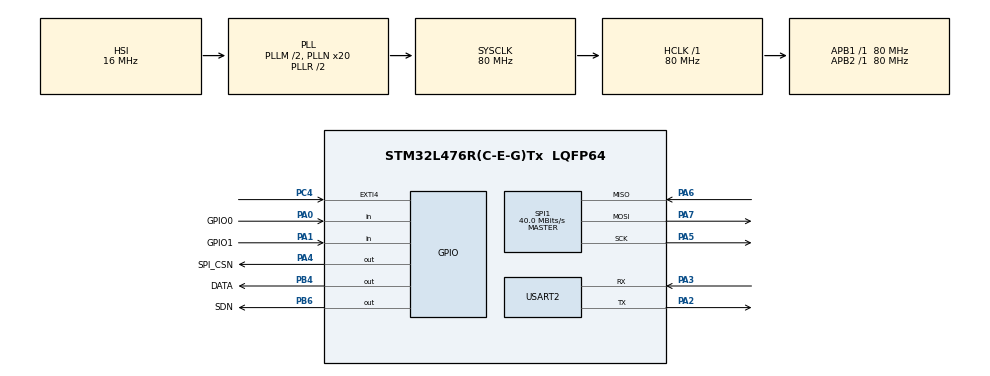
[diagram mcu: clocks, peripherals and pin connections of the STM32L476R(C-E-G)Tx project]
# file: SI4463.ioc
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Mcu.Family=STM32L4
Mcu.Name=STM32L476R(C-E-G)Tx
Mcu.Package=LQFP64
NVIC.EXTI4_IRQn=true\:1\:1\:true\:false\:true\:true\:true
NVIC.PriorityGroup=NVIC_PRIORITYGROUP_2
PA0.GPIO_Label=GPIO0
PA0.GPIO_PuPd=GPIO_PULLUP
PA0.Signal=GPIO_Input
PA1.GPIO_Label=GPIO1
PA1.GPIO_PuPd=GPIO_PULLUP
PA1.Signal=GPIO_Input
PA13.Mode=Serial-Wire
PA13.Signal=SYS_JTMS-SWDIO
PA14.Mode=Serial-Wire
PA14.Signal=SYS_JTCK-SWCLK
PA2.Mode=Asynchronous
PA2.Signal=USART2_TX
PA3.Mode=Asynchronous
PA3.Signal=USART2_RX
PA4.GPIO_Label=SPI_CSN
PA4.GPIO_PuPd=GPIO_PULLUP
PA4.GPIO_Speed=GPIO_SPEED_HIGH
PA4.Signal=GPIO_Output
PA5.GPIO_PuPd=GPIO_PULLUP
PA5.Mode=Full_Duplex_Master
PA5.Signal=SPI1_SCK
PA6.GPIO_PuPd=GPIO_PULLUP
PA6.Mode=Full_Duplex_Master
PA6.Signal=SPI1_MISO
PA7.GPIO_PuPd=GPIO_PULLUP
PA7.Mode=Full_Duplex_Master
PA7.Signal=SPI1_MOSI
PB4.GPIO_Label=DATA
PB4.GPIO_ModeDefaultOutputPP=GPIO_MODE_OUTPUT_PP
PB4.GPIO_PuPd=GPIO_PULLUP
PB4.GPIO_Speed=GPIO_SPEED_HIGH
PB4.Signal=GPIO_Output
PB6.GPIO_FM6=I2C_FASTMODEPLUS_PB6
PB6.GPIO_Label=SDN
PB6.GPIO_PuPd=GPIO_PULLUP
PB6.GPIO_Speed=GPIO_SPEED_HIGH
PB6.Signal=GPIO_Output
PC14/OSC32_IN.Mode=LSE-External-Oscillator
PC14/OSC32_IN.Signal=RCC_OSC32_IN
PC15/OSC32_OUT.Mode=LSE-External-Oscillator
PC15/OSC32_OUT.Signal=RCC_OSC32_OUT
PC4.GPIO_ModeDefaultEXTI=GPIO_MODE_IT_FALLING
PC4.GPIO_PuPd=GPIO_PULLUP
PC4.Signal=GPXTI4
PH0/OSC_IN.Mode=HSE-External-Oscillator
PH0/OSC_IN.Signal=RCC_OSC_IN
PH1/OSC_OUT.Mode=HSE-External-Oscillator
PH1/OSC_OUT.Signal=RCC_OSC_OUT
ProjectManager.HeapSize=0x200
ProjectManager.StackSize=0x400
ProjectManager.TargetToolchain=MDK-ARM V5.27
RCC.ADCFreq_Value=48000000
RCC.AHBFreq_Value=80000000
RCC.APB1Freq_Value=80000000
RCC.APB1TimFreq_Value=80000000
RCC.APB2Freq_Value=80000000
RCC.APB2TimFreq_Value=80000000
RCC.CortexFreq_Value=80000000
RCC.HCLKFreq_Value=80000000
RCC.HSE_VALUE=8000000
RCC.HSI_VALUE=16000000
RCC.MSI_VALUE=4000000
RCC.PLLM=2
RCC.PLLN=20
RCC.PLLSAI1N=12
RCC.PLLSourceVirtual=RCC_PLLSOURCE_HSI
RCC.SYSCLKFreq_VALUE=80000000
RCC.SYSCLKSource=RCC_SYSCLKSOURCE_PLLCLK
RCC.USART2CLockSelection=RCC_USART2CLKSOURCE_SYSCLK
RCC.USBFreq_Value=48000000
RCC.VCOOutputFreq_Value=160000000
SPI1.BaudRatePrescaler=SPI_BAUDRATEPRESCALER_2
SPI1.CalculateBaudRate=40.0 MBits/s
SPI1.DataSize=SPI_DATASIZE_8BIT
SPI1.Direction=SPI_DIRECTION_2LINES
SPI1.Mode=SPI_MODE_MASTER
SPI1.NSSPMode=SPI_NSS_PULSE_DISABLED
SPI1.VirtualType=VM_MASTER
USART2.VirtualMode-Asynchronous=VM_ASYNC
USART2.WordLength=UART_WORDLENGTH_8B
board=SI4463

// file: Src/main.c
/**
  ******************************************************************************
  * File Name          : main.c
  * Description        : Main program body
  ******************************************************************************
  *
  * COPYRIGHT(c) 2021 STMicroelectronics
  *
  * Redistribution and use in source and binary forms, with or without modification,
  * are permitted provided that the following conditions are met:
  *   1. Redistributions of source code must retain the above copyright notice,
  *      this list of conditions and the following disclaimer.
  *   2. Redistributions in binary form must reproduce the above copyright notice,
  *      this list of conditions and the following disclaimer in the documentation
  *      and/or other materials provided with the distribution.
  *   3. Neither the name of STMicroelectronics nor the names of its contributors
  *      may be used to endorse or promote products derived from this software
  *      without specific prior written permission.
  *
  * THIS SOFTWARE IS PROVIDED BY THE COPYRIGHT HOLDERS AND CONTRIBUTORS "AS IS"
  * AND ANY EXPRESS OR IMPLIED WARRANTIES, INCLUDING, BUT NOT LIMITED TO, THE
  * IMPLIED WARRANTIES OF MERCHANTABILITY AND FITNESS FOR A PARTICULAR PURPOSE ARE
  * DISCLAIMED. IN NO EVENT SHALL THE COPYRIGHT HOLDER OR CONTRIBUTORS BE LIABLE
  * FOR ANY DIRECT, INDIRECT, INCIDENTAL, SPECIAL, EXEMPLARY, OR CONSEQUENTIAL
  * DAMAGES (INCLUDING, BUT NOT LIMITED TO, PROCUREMENT OF SUBSTITUTE GOODS OR
  * SERVICES; LOSS OF USE, DATA, OR PROFITS; OR BUSINESS INTERRUPTION) HOWEVER
  * CAUSED AND ON ANY THEORY OF LIABILITY, WHETHER IN CONTRACT, STRICT LIABILITY,
  * OR TORT (INCLUDING NEGLIGENCE OR OTHERWISE) ARISING IN ANY WAY OUT OF THE USE
  * OF THIS SOFTWARE, EVEN IF ADVISED OF THE POSSIBILITY OF SUCH DAMAGE.
  *
  ******************************************************************************
  */
#include "stm32l4xx_hal.h"
#include "spi.h"
#include "usart.h"
#include "gpio.h"

/* USER CODE BEGIN Includes */
#include "bsp.h"
//#include "si4463.h"
/* USER CODE END Includes */

/* USER CODE BEGIN PV */
/* Private variables ---------------------------------------------------------*/

/* USER CODE END PV */

void SystemClock_Config(void);

/* USER CODE BEGIN PFP */
/* Private function prototypes -----------------------------------------------*/

/* USER CODE END PFP */

/* USER CODE BEGIN 0 */
uint8_t pro_state[8]={0};
/* USER CODE END 0 */

int main(void)
{

  /* MCU Configuration----------------------------------------------------------*/

  /* Reset of all peripherals, Initializes the Flash interface and the Systick. */
  HAL_Init();

  /* Configure the system clock */
  SystemClock_Config();

  /* Initialize all configured peripherals */
  MX_GPIO_Init();
  SystemClock_Config();
  MX_SPI1_Init();
  MX_USART2_UART_Init();

  /* USER CODE BEGIN 2 */
  printf("HCLK=%d\r\n",HAL_RCC_GetHCLKFreq());
  SI446X_SPI_INIT();
  SI446X_RESET( );                                //SI446X 模块复位
  SI446X_CONFIG_INIT( );                          //寄存器初始化，寄存器来自WDS配置的头文件
  SI446X_SET_POWER( 0x7F );                       //将输出功率配置为最大
  SI446X_START_TX( 0, 0, 0 );   //进入接收模式，参数定义详见API手册
  SI446X_PART_INFO(pro_state);
  /* USER CODE END 2 */

  /* Infinite loop */
  /* USER CODE BEGIN WHILE */
  int t=0;
  while (1)
  {
  /* USER CODE END WHILE */
		HAL_GPIO_WritePin(DATA_GPIO_Port,DATA_Pin,GPIO_PIN_RESET);
		t=0;
		while(t<1000000)
			t++;
		HAL_GPIO_WritePin(DATA_GPIO_Port,DATA_Pin,GPIO_PIN_SET);
		t=0;
		while(t<1000000)
			t++;
  }

}

/** System Clock Configuration
*/
void SystemClock_Config(void)
{

  RCC_OscInitTypeDef RCC_OscInitStruct;
  RCC_ClkInitTypeDef RCC_ClkInitStruct;
  RCC_PeriphCLKInitTypeDef PeriphClkInit;

  RCC_OscInitStruct.OscillatorType = RCC_OSCILLATORTYPE_HSI;
  RCC_OscInitStruct.HSIState = RCC_HSI_ON;
  RCC_OscInitStruct.HSICalibrationValue = 16;
  RCC_OscInitStruct.PLL.PLLState = RCC_PLL_ON;
  RCC_OscInitStruct.PLL.PLLSource = RCC_PLLSOURCE_HSI;
  RCC_OscInitStruct.PLL.PLLM = 2;
  RCC_OscInitStruct.PLL.PLLN = 20;
  RCC_OscInitStruct.PLL.PLLP = RCC_PLLP_DIV7;
  RCC_OscInitStruct.PLL.PLLQ = RCC_PLLQ_DIV2;
  RCC_OscInitStruct.PLL.PLLR = RCC_PLLR_DIV2;
  HAL_RCC_OscConfig(&RCC_OscInitStruct);

  RCC_ClkInitStruct.ClockType = RCC_CLOCKTYPE_HCLK|RCC_CLOCKTYPE_SYSCLK
                              |RCC_CLOCKTYPE_PCLK1|RCC_CLOCKTYPE_PCLK2;
  RCC_ClkInitStruct.SYSCLKSource = RCC_SYSCLKSOURCE_PLLCLK;
  RCC_ClkInitStruct.AHBCLKDivider = RCC_SYSCLK_DIV1;
  RCC_ClkInitStruct.APB1CLKDivider = RCC_HCLK_DIV1;
  RCC_ClkInitStruct.APB2CLKDivider = RCC_HCLK_DIV1;
  HAL_RCC_ClockConfig(&RCC_ClkInitStruct, FLASH_LATENCY_4);

  PeriphClkInit.PeriphClockSelection = RCC_PERIPHCLK_USART2;
  PeriphClkInit.Usart2ClockSelection = RCC_USART2CLKSOURCE_SYSCLK;
  HAL_RCCEx_PeriphCLKConfig(&PeriphClkInit);

  __PWR_CLK_ENABLE();

  HAL_PWREx_ControlVoltageScaling(PWR_REGULATOR_VOLTAGE_SCALE1);

  HAL_SYSTICK_Config(HAL_RCC_GetHCLKFreq()/1000);

  HAL_SYSTICK_CLKSourceConfig(SYSTICK_CLKSOURCE_HCLK);

  /* SysTick_IRQn interrupt configuration */
  HAL_NVIC_SetPriority(SysTick_IRQn, 0, 0);
}

/************************ (C) COPYRIGHT STMicroelectronics *****END OF FILE****/
